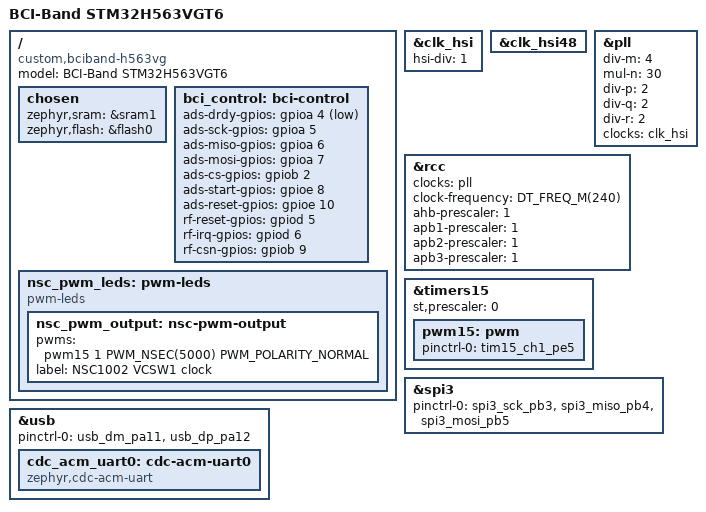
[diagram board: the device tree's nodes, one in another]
/dts-v1/;

#include <st/h5/stm32h563Xg.dtsi>
#include <st/h5/stm32h563vgtx-pinctrl.dtsi>
#include <zephyr/dt-bindings/gpio/gpio.h>
#include <zephyr/dt-bindings/pwm/pwm.h>

/ {
	model = "BCI-Band STM32H563VGT6";
	compatible = "custom,bciband-h563vg";

	#address-cells = <1>;
	#size-cells = <1>;

	chosen {
		zephyr,sram = &sram1;
		zephyr,flash = &flash0;
	};

	bci_control: bci-control {
		ads-drdy-gpios = <&gpioa 4 (GPIO_ACTIVE_LOW | GPIO_PULL_UP)>;
		ads-sck-gpios = <&gpioa 5 GPIO_ACTIVE_HIGH>;
		ads-miso-gpios = <&gpioa 6 GPIO_ACTIVE_HIGH>;
		ads-mosi-gpios = <&gpioa 7 GPIO_ACTIVE_HIGH>;
		ads-cs-gpios = <&gpiob 2 GPIO_ACTIVE_HIGH>;
		ads-start-gpios = <&gpioe 8 GPIO_ACTIVE_HIGH>;
		ads-reset-gpios = <&gpioe 10 GPIO_ACTIVE_HIGH>;

		rf-reset-gpios = <&gpiod 5 GPIO_ACTIVE_HIGH>;
		rf-irq-gpios = <&gpiod 6 (GPIO_ACTIVE_HIGH | GPIO_PULL_DOWN)>;
		rf-csn-gpios = <&gpiob 9 GPIO_ACTIVE_HIGH>;
	};

	nsc_pwm_leds: pwm-leds {
		compatible = "pwm-leds";

		nsc_pwm_output: nsc-pwm-output {
			pwms = <&pwm15 1 PWM_NSEC(5000) PWM_POLARITY_NORMAL>;
			label = "NSC1002 VCSW1 clock";
		};
	};
};

&clk_hsi {
	hsi-div = <1>;
	status = "okay";
};

&clk_hsi48 {
	status = "okay";
};

&pll {
	div-m = <4>;
	mul-n = <30>;
	div-p = <2>;
	div-q = <2>;
	div-r = <2>;
	clocks = <&clk_hsi>;
	status = "okay";
};

&rcc {
	clocks = <&pll>;
	clock-frequency = <DT_FREQ_M(240)>;
	ahb-prescaler = <1>;
	apb1-prescaler = <1>;
	apb2-prescaler = <1>;
	apb3-prescaler = <1>;
};

&timers15 {
	st,prescaler = <0>;
	status = "okay";

	pwm15: pwm {
		pinctrl-0 = <&tim15_ch1_pe5>;
		pinctrl-names = "default";
		status = "okay";
	};
};

&spi3 {
	pinctrl-0 = <&spi3_sck_pb3 &spi3_miso_pb4 &spi3_mosi_pb5>;
	pinctrl-names = "default";
	status = "okay";
};

zephyr_udc0: &usb {
	pinctrl-0 = <&usb_dm_pa11 &usb_dp_pa12>;
	pinctrl-names = "default";
	status = "okay";

	cdc_acm_uart0: cdc-acm-uart0 {
		compatible = "zephyr,cdc-acm-uart";
	};
};
